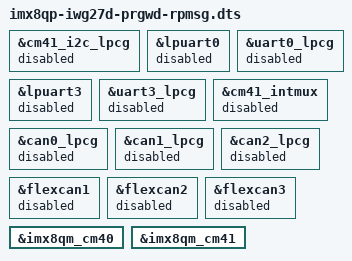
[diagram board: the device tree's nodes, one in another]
// SPDX-License-Identifier: GPL-2.0+
/*
 * Copyright (c) 2021-22 iWave Systems Technologies Pvt. Ltd.
 *
 * This program is free software; you can redistribute it and/or
 * modify it under the terms of the GNU General Public License
 * as published by the Free Software Foundation; either version 2
 * of the License, or (at your option) any later version.
 *
 * This program is distributed in the hope that it will be useful,
 * but WITHOUT ANY WARRANTY; without even the implied warranty of
 * MERCHANTABILITY or FITNESS FOR A PARTICULAR PURPOSE.  See the
 * GNU General Public License for more details.
 */

/dts-v1/;

#include "imx8qp-iwg27d-prgwd.dts"

/delete-node/ &cm41_i2c;

&cm41_i2c_lpcg {
	status = "disabled";
};

&lpuart0 {
        status = "disabled";
};

&uart0_lpcg {
        status = "disabled";
};

&lpuart3 {
        status = "disabled";
};

&uart3_lpcg {
        status = "disabled";
};

&cm41_intmux {
	status = "disabled";
};

&can0_lpcg {
	status = "disabled";
};

&can1_lpcg {
	status = "disabled";
};

&can2_lpcg {
	status = "disabled";
};

&flexcan1 {
	status = "disabled";
};

&flexcan2 {
	status = "disabled";
};

&flexcan3 {
	status = "disabled";
};

&imx8qm_cm40 {
        /* Assume you have partitioned M4, so M4 is ont controled by Linux */
        /delete-property/ power-domains;
};

&imx8qm_cm41 {
        /* Assume you have partitioned M4, so M4 is ont controled by Linux */
        /delete-property/ power-domains;
};
